# f28p65x_cpu2_sys_status_regs register map
Vendor: Texas Instruments
Peripheral module from a debugger description file (folder C2000).
Address unit: 16 bits
Registers are 32-bit, read-write, no defined reset value unless marked. A register's access mark holds for its fields unless they carry their own. Offsets are as the file gives them; lines under a group give offsets from that group; [hi:lo] are bit positions; {n}, {i} and the like mark numbered series; 'fields as' and 'values as' point back to an identical list; <NAME> marks a mode.

## CPU2_SYS_STATUS_REGS — CPU2 SYS STATUS Registers
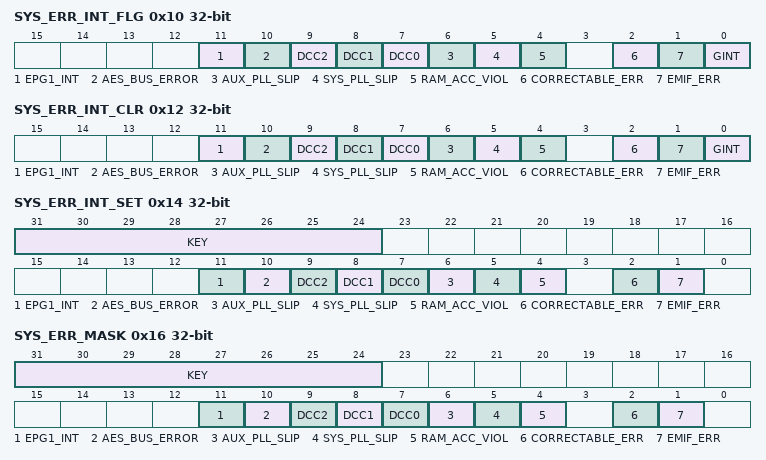
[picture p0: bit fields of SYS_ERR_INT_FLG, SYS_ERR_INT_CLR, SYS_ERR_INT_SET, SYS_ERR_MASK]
0x10 SYS_ERR_INT_FLG ro — Status of interrupts due to multiple different errors in the system.
  [11] EPG1_INT — EPG1_INT Interrupt flag.
  [10] AES_BUS_ERROR — AES_BUS_ERROR Interrupt flag.
  [9] DCC2 — DCC2 Interrupt flag.
  [8] DCC1 — DCC1 Interrupt flag.
  [7] DCC0 — DCC0 Interrupt flag.
  [6] AUX_PLL_SLIP — Auxillary PLL Slip event flag.
  [5] SYS_PLL_SLIP — System PLL Slip event flag.
  [4] RAM_ACC_VIOL — A RAM access vioation flag.
  [2] CORRECTABLE_ERR — RAM/Flash correctable error flag
  [1] EMIF_ERR — EMIF error event flag
  [0] GINT — Global Interrupt flag
0x12 SYS_ERR_INT_CLR — SYS_ERR_INT_FLG clear register
  [11] EPG1_INT — EPG1_INT interrupt flag clear bit
  [10] AES_BUS_ERROR — AES_BUS_ERROR interrupt flag clear bit
  [9] DCC2 — DCC2 interrupt flag clear bit
  [8] DCC1 — DCC1 interrupt flag clear bit
  [7] DCC0 — DCC0 interrupt flag clear bit
  [6] AUX_PLL_SLIP — AUX_PLL_SLIP interrupt flag clear bit
  [5] SYS_PLL_SLIP — SYS_PLL_SLIP interrupt flag clear bit
  [4] RAM_ACC_VIOL — RAM_ACC_VIOL interrupt flag clear bit
  [2] CORRECTABLE_ERR — CORRECTABLE_ERR interrupt flag clear bit
  [1] EMIF_ERR — EMIF_ERR interrupt flag clear bit
  [0] GINT — Global Interrupt flag Clear bit
0x14 SYS_ERR_INT_SET — SYS_ERR_INT_FLG set register
  [31:24] KEY
  [11] EPG1_INT — EPG1_INT interrupt flag set bit
  [10] AES_BUS_ERROR — AES_BUS_ERROR interrupt flag set bit
  [9] DCC2 — DCC2 interrupt flag set bit
  [8] DCC1 — DCC1 interrupt flag set bit
  [7] DCC0 — DCC0 interrupt flag set bit
  [6] AUX_PLL_SLIP — AUX_PLL_SLIP interrupt flag set bit
  [5] SYS_PLL_SLIP — SYS_PLL_SLIP interrupt flag set bit
  [4] RAM_ACC_VIOL — RAM_ACC_VIOL interrupt flag set bit
  [2] CORRECTABLE_ERR — CORRECTABLE_ERR interrupt flag set bit
  [1] EMIF_ERR — EMIF_ERR interrupt flag set bit
0x16 SYS_ERR_MASK
  [31:24] KEY
  [11] EPG1_INT — EPG1_INT flag mask bit
  [10] AES_BUS_ERROR — AES_BUS_ERROR flag mask bit
  [9] DCC2 — DCC2 flag mask bit
  [8] DCC1 — DCC1 flag mask bit
  [7] DCC0 — DCC0 flag mask bit
  [6] AUX_PLL_SLIP — AUX_PLL_SLIP flag mask bit
  [5] SYS_PLL_SLIP — SYS_PLL_SLIP flag mask bit
  [4] RAM_ACC_VIOL — RAM_ACC_VIOL flag mask bit
  [2] CORRECTABLE_ERR — CORRECTABLE_ERR flag mask bit
  [1] EMIF_ERR — EMIF_ERR flag mask bit
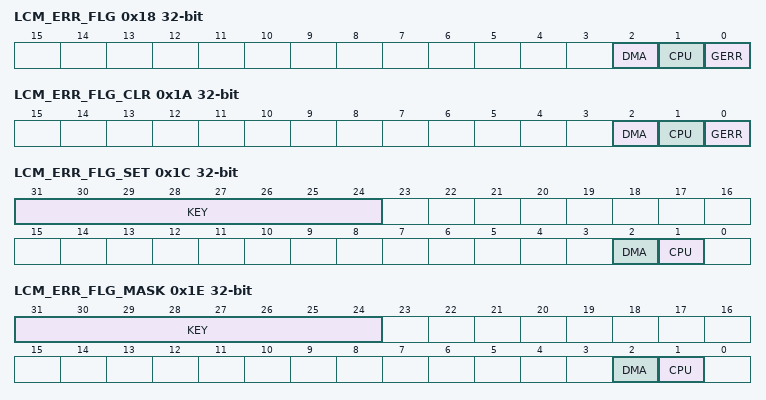
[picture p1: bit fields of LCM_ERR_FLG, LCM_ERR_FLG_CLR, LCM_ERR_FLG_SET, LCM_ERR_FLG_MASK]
0x18 LCM_ERR_FLG ro — Status register indicating lockstep compare error flag
  [2] DMA — DMA Lokstep Miscompare flag
  [1] CPU — CPU Lokstep Miscompare flag
  [0] GERR — Global Error event flag
0x1A LCM_ERR_FLG_CLR — LCM_ERR_FLG clear register
  fields as LCM_ERR_FLG
0x1C LCM_ERR_FLG_SET
  [31:24] KEY
  [2] DMA — DMA Lokstep Miscompare flag set
  [1] CPU — CPU Lokstep Miscompare flag set
0x1E LCM_ERR_FLG_MASK
  [31:24] KEY
  [2] DMA — DMA Lokstep Miscompare flag mask
  [1] CPU — CPU Lokstep Miscompare flag mask
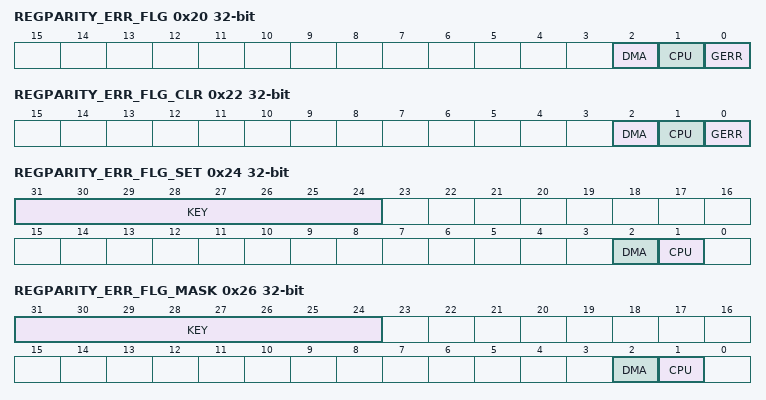
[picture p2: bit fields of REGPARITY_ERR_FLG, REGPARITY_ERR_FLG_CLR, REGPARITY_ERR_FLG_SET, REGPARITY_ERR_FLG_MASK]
0x20 REGPARITY_ERR_FLG ro — Status register indicating register parity error flag
  [2] DMA — Register parity error from lockstep compare module
  [1] CPU — Register parity error from lockstep compare module
  [0] GERR — Global Error event flag
0x22 REGPARITY_ERR_FLG_CLR — REGPARITY_ERR_FLG clear register
  [2] DMA — Register parity error from lockstep compare module clear
  [1] CPU — Register parity error from lockstep compare module clear
  [0] GERR — Global Error event flag clear
0x24 REGPARITY_ERR_FLG_SET
  [31:24] KEY
  [2] DMA — Register parity error from lockstep compare module set
  [1] CPU — Register parity error from lockstep compare module set
0x26 REGPARITY_ERR_FLG_MASK
  [31:24] KEY
  [2] DMA — Register parity error from lockstep compare module mask
  [1] CPU — Register parity error from lockstep compare module mask
